AUTOSAR XML (schema 4-3-0)
standard types defined: float32, sint16, uint16, uint32, uint8, float32_DataConstr, sint16_DataConstr, uint16_DataConstr, uint32_DataConstr, uint8_DataConstr, boolean, sint32
package /ASP_DataTypes
  44 x impl type, all with category=VALUE:
    accPedalPosition: base-type=BaseTypes/uint8
    accPedalPositionQual: base-type=BaseTypes/uint8, compu {0=Cx0_Unsafe, 1=Cx1_Safe, 2=Cx2_SNA; unit Enum}
    brakePedalPressed: base-type=boolean, compu {0=Cx0_No, 1=Cx1_Yes; unit Enum}
    brakePedalPressedQual: base-type=BaseTypes/uint8, compu {0=Cx0_Unsafe, 1=Cx1_Safe, 2=Cx2_SNA; unit Enum}
    brakeTorque: base-type=BaseTypes/uint16
    collAvoidSnvtySetting: base-type=BaseTypes/uint8, compu {0=Cx0_NotInUse, 1=Cx1_LoSnvty, 2=Cx2_NormSnvty, 3=Cx3_HiSnvty; unit Enum}
    collAvoidSnvtySettingQual: base-type=BaseTypes/uint8, compu {0=Cx0_Unsafe, 1=Cx1_Safe, 2=Cx2_SNA; unit Enum}
    driverAEBOverride: base-type=boolean, compu {0=Cx0_No, 1=Cx1_Yes; unit Enum}
    driverAEBOverrideQual: base-type=BaseTypes/uint8, compu {0=Cx0_Unsafe, 1=Cx1_Safe, 2=Cx2_SNA; unit Enum}
    driverBrakeTorque: base-type=BaseTypes/uint16
    driverBrakeTorqueQual: base-type=BaseTypes/uint8, compu {0=Cx0_Unsafe, 1=Cx1_Safe, 2=Cx2_SNA; unit Enum}
    dynamicWheelRadiusFront: base-type=BaseTypes/uint16
    dynamicWheelRadiusRear: base-type=BaseTypes/uint16
    engineState: base-type=BaseTypes/uint8, compu {0=Cx0_Stop, 1=Cx1_Start, 2=Cx2_Idle_Unstable (Idle Unstable), 3=Cx3_Idle_Stable (Idle Stable), 4=Cx4_Unlimited, 5=Cx5_Limited, 6=Cx6_SNA; unit Enum}
    frontWheelAngle: base-type=BaseTypes/sint16
    frontWheelAngleQual: base-type=BaseTypes/uint8, compu {0=Cx0_Unavailable, 1=Cx1_Available, 2=Cx2_SNA; unit Enum}
    ignitionState: base-type=BaseTypes/uint8, compu {0=Cx0_Lock, 1=Cx1_OFF, 2=Cx2_ACC, 3=Cx3_ON, 4=Cx4_Start, 5=Cx5_SNA; unit Enum}
    lateralAcceleration: base-type=BaseTypes/sint16
    lateralAccelerationQual: base-type=BaseTypes/uint8, compu {0=Cx0_Unavailable, 1=Cx1_Available, 2=Cx2_SNA; unit Enum}
    lateralAccRaw: base-type=BaseTypes/sint16
    lateralAccRawQual: base-type=BaseTypes/uint8, compu {0=Cx0_Unsafe, 1=Cx1_Safe, 2=Cx2_SNA; unit Enum}
    longitudinalAcceleration: base-type=BaseTypes/sint16
    longitudinalAccelerationQual: base-type=BaseTypes/uint8, compu {0=Cx0_Unavailable, 1=Cx1_Available, 2=Cx2_SNA; unit Enum}
    longitudinalAccRaw: base-type=BaseTypes/sint16
    longitudinalAccRawQual: base-type=BaseTypes/uint8, compu {0=Cx0_Unsafe, 1=Cx1_Safe, 2=Cx2_SNA; unit Enum}
    longitudinalSpeed: base-type=BaseTypes/sint16
    longitudinalSpeedQual: base-type=BaseTypes/uint8, compu {0=Cx0_Unsafe, 1=Cx1_Safe, 2=Cx2_SNA; unit Enum}
    rearWheelAngle: base-type=BaseTypes/sint16
    rearWheelAngleQual: base-type=BaseTypes/uint8, compu {0=Cx0_Unavailable, 1=Cx1_Available, 2=Cx2_SNA; unit Enum}
    steeringWhlAngle: base-type=BaseTypes/sint16
    steeringWhlAngleQual: base-type=BaseTypes/uint8, compu {0=Cx0_Unsafe, 1=Cx1_Safe, 2=Cx2_SNA; unit Enum}
    steeringWhlAngleSpeed: base-type=sint32
    steeringWhlAngleSpeedQual: base-type=BaseTypes/uint8, compu {0=Cx0_Unsafe, 1=Cx1_Safe, 2=Cx2_SNA; unit Enum}
    suspensionType: base-type=BaseTypes/uint8
    turnIndicator: base-type=BaseTypes/uint8
    vehicleMotionState: base-type=BaseTypes/uint8, compu {0=Cx0_Ukwn, 1=Cx1_StandStillVal1, 2=Cx2_StandStillVal2, 3=Cx3_StandStillVal3, 4=Cx4_RollgFwdVal1, 5=Cx5_RollgFwdVal2, 6=Cx6_RollgBackwVal1, 7=Cx7_RollgBackwVal2; unit Enum}
    vehicleMotionStateQual: base-type=BaseTypes/uint8, compu {0=Cx0_Unsafe, 1=Cx1_Safe, 2=Cx2_SNA; unit Enum}
    wheelSpeedFrontLeft: base-type=BaseTypes/sint16
    wheelSpeedFrontRight: base-type=BaseTypes/sint16
    wheelSpeedQual: base-type=BaseTypes/uint8, compu {0=Cx0_Unavailable, 1=Cx1_Available, 2=Cx2_SNA; unit Enum}
    wheelSpeedRearLeft: base-type=BaseTypes/sint16
    wheelSpeedRearRight: base-type=BaseTypes/sint16
    yawRate: base-type=BaseTypes/sint16
    yawRateQual: base-type=BaseTypes/uint8, compu {0=Cx0_Unavailable, 1=Cx1_Available, 2=Cx2_SNA; unit Enum}
package /ASP_DataTypes/Units
  unit U_Enum: display-name=Enum, factor-si-to-unit=1, offset-si-to-unit=0
package /ComponentTypes/HkmcVehicleInputSWC
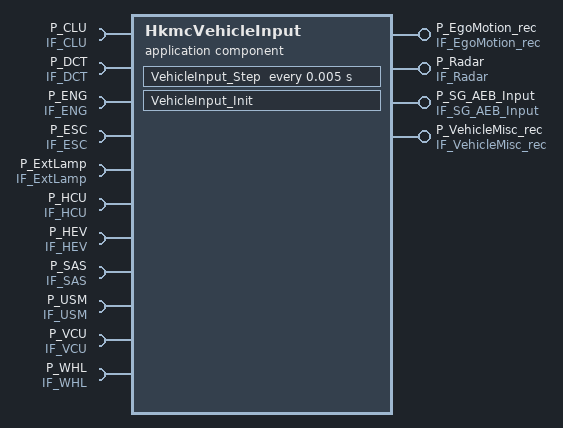
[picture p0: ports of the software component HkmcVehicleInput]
  application sw component type HkmcVehicleInput
    4 x provide port:
      P_EgoMotion_rec: nonqueued-sender-com-spec{data-element=DE_EgoMotion_rec, init-value=constant-reference=CS_VehicleInput_EgoMotion_rec}, provided-interface=IF_EgoMotion_rec
      P_Radar: nonqueued-sender-com-spec{data-element=DE_Radar, init-value=constant-reference=CS_VehicleInput_Radar}, provided-interface=IF_Radar
      P_SG_AEB_Input: nonqueued-sender-com-spec{data-element=DE_SG_AEB_Input, init-value=constant-reference=CS_VehicleInput_SG_AEB_Input}, provided-interface=IF_SG_AEB_Input
      P_VehicleMisc_rec: nonqueued-sender-com-spec{data-element=DE_VehicleMisc_rec, init-value=constant-reference=CS_VehicleInput_VehicleMisc_rec}, provided-interface=IF_VehicleMisc_rec
    11 x require port:
      P_CLU: nonqueued-receiver-com-spec{data-element=DE_CLU, filter=data-filter-type=ALWAYS, init-value=constant-reference=CS_Vehicle_CLU}, required-interface=IF_CLU
      P_DCT: nonqueued-receiver-com-spec{data-element=DE_DCT, filter=data-filter-type=ALWAYS, init-value=constant-reference=CS_VehicleInput_DCT}, required-interface=IF_DCT
      P_ENG: nonqueued-receiver-com-spec{data-element=DE_ENG, filter=data-filter-type=ALWAYS, init-value=constant-reference=CS_VehicleInput_ENG}, required-interface=IF_ENG
      P_ESC: nonqueued-receiver-com-spec{data-element=DE_ESC, filter=data-filter-type=ALWAYS, init-value=constant-reference=CS_VehicleInput_ESC}, required-interface=IF_ESC
      P_ExtLamp: nonqueued-receiver-com-spec{data-element=DE_ExtLamp, filter=data-filter-type=ALWAYS, init-value=constant-reference=CS_VehicleInput_ExtLamp}, required-interface=IF_ExtLamp
      P_HCU: nonqueued-receiver-com-spec{data-element=DE_HCU, filter=data-filter-type=ALWAYS, init-value=constant-reference=CS_Vehicle_HCU}, required-interface=IF_HCU
      P_HEV: nonqueued-receiver-com-spec{data-element=DE_HEV, filter=data-filter-type=ALWAYS, init-value=constant-reference=CS_VehicleInput_HEV}, required-interface=IF_HEV
      P_SAS: nonqueued-receiver-com-spec{data-element=DE_SAS, filter=data-filter-type=ALWAYS, init-value=constant-reference=CS_VehicleInput_SAS}, required-interface=IF_SAS
      P_USM: nonqueued-receiver-com-spec{data-element=DE_USM, filter=data-filter-type=ALWAYS, init-value=constant-reference=CS_VehicleInput_USM}, required-interface=IF_USM
      P_VCU: nonqueued-receiver-com-spec{data-element=DE_VCU, filter=data-filter-type=ALWAYS, init-value=constant-reference=CS_Vehicle_VCU}, required-interface=IF_VCU
      P_WHL: nonqueued-receiver-com-spec{data-element=DE_WHL, filter=data-filter-type=ALWAYS, init-value=constant-reference=CS_VehicleInput_WHL}, required-interface=IF_WHL
    behavior HkmcVehicleInput_InternalBehavior
      init event VehicleInput_InitEvent: start-on-event=VehicleInput_Init
      timing event VehicleInput_Step_TE: start-on-event=VehicleInput_Step, period=0.005
      runnable VehicleInput_Init
        data-receive-point-by-arguments:
          11 x access:
            REC_P_CLU_DE_CLU: accessed-variable=P_CLU.DE_CLU
            REC_P_DCT_DE_DCT: accessed-variable=P_DCT.DE_DCT
            REC_P_ENG_DE_ENG: accessed-variable=P_ENG.DE_ENG
            REC_P_ESC_DE_ESC: accessed-variable=P_ESC.DE_ESC
            REC_P_ExtLamp_DE_ExtLamp: accessed-variable=P_ExtLamp.DE_ExtLamp
            REC_P_HCU_DE_HCU: accessed-variable=P_HCU.DE_HCU
            REC_P_HEV_DE_HEV: accessed-variable=P_HEV.DE_HEV
            REC_P_SAS_DE_SAS: accessed-variable=P_SAS.DE_SAS
            REC_P_USM_DE_USM: accessed-variable=P_USM.DE_USM
            REC_P_VCU_DE_VCU: accessed-variable=P_VCU.DE_VCU
            REC_P_WHL_DE_WHL: accessed-variable=P_WHL.DE_WHL
        data-send-points:
          4 x access:
            SEND_P_EgoMotion_rec_DE_EgoMotion_rec: accessed-variable=P_EgoMotion_rec.DE_EgoMotion_rec
            SEND_P_Radar_DE_Radar: accessed-variable=P_Radar.DE_Radar
            SEND_P_SG_AEB_Input_DE_SG_AEB_Input: accessed-variable=P_SG_AEB_Input.DE_SG_AEB_Input
            SEND_P_VehicleMisc_rec_DE_VehicleMisc_rec: accessed-variable=P_VehicleMisc_rec.DE_VehicleMisc_rec
      runnable VehicleInput_Step
        data-receive-point-by-arguments:
          11 x access:
            REC_P_CLU_DE_CLU: accessed-variable=P_CLU.DE_CLU
            REC_P_DCT_DE_DCT: accessed-variable=P_DCT.DE_DCT
            REC_P_ENG_DE_ENG: accessed-variable=P_ENG.DE_ENG
            REC_P_ESC_DE_ESC: accessed-variable=P_ESC.DE_ESC
            REC_P_ExtLamp_DE_ExtLamp: accessed-variable=P_ExtLamp.DE_ExtLamp
            REC_P_HCU_DE_HCU: accessed-variable=P_HCU.DE_HCU
            REC_P_HEV_DE_HEV: accessed-variable=P_HEV.DE_HEV
            REC_P_SAS_DE_SAS: accessed-variable=P_SAS.DE_SAS
            REC_P_USM_DE_USM: accessed-variable=P_USM.DE_USM
            REC_P_VCU_DE_VCU: accessed-variable=P_VCU.DE_VCU
            REC_P_WHL_DE_WHL: accessed-variable=P_WHL.DE_WHL
        data-send-points:
          4 x access:
            SEND_P_EgoMotion_rec_DE_EgoMotion_rec: accessed-variable=P_EgoMotion_rec.DE_EgoMotion_rec
            SEND_P_Radar_DE_Radar: accessed-variable=P_Radar.DE_Radar
            SEND_P_SG_AEB_Input_DE_SG_AEB_Input: accessed-variable=P_SG_AEB_Input.DE_SG_AEB_Input
            SEND_P_VehicleMisc_rec_DE_VehicleMisc_rec: accessed-variable=P_VehicleMisc_rec.DE_VehicleMisc_rec
  swc implementation HkmcVehicleInput_Implementation: behavior=HkmcVehicleInput_InternalBehavior
    code-descriptors:
      code Default: artifact-descriptors=autosar-engineering-object={short-label=Default, category=SWSRC}
package /ComponentTypes/HkmcVehicleInputSWC/Constants
  15 x constant specification:
    CS_Vehicle_CLU: value-spec=fields=CLU_OdoVal:0
    CS_Vehicle_HCU: value-spec=fields=HCU_HevRdySta:0
    CS_Vehicle_VCU: value-spec=fields=VCU_EVRdySta:0
    CS_VehicleInput_DCT: value-spec=fields=DCT_AccelPdlVal:0
    CS_VehicleInput_EgoMotion_rec: value-spec=fields=[dynamicWheelRadiusRear:0, lateralAccelerationQual:0, lateralAcceleration:0, longitudinalSpeedQual:0, wheelSpeedFrontRight:0, dynamicWheelRadiusFront:0, wheelSpeedQual:0, wheelSpeedFrontLeft:0, longitudinalSpeed:0, rearWheelAngleQual:0, wheelSpeedRearRight:0, longitudinalAccelerationQual:0, frontWheelAngle:0, rearWheelAngle:0, wheelSpeedRearLeft:0, frontWheelAngleQual:0, longitudinalAcceleration:0, yawRate:0, yawRateQual:0, brakeTorque:0]
    CS_VehicleInput_ENG: value-spec=fields=[ENG_IsgOnSta:0, ENG_EngSta:0, ENG_AccelPdlVal:0]
    CS_VehicleInput_ESC: value-spec=fields=[ESC_YawSigSta:0, ESC_LongAccelSigSta:0, ESC_YawRtVal:0, ESC_LongAccelVal:0, ESC_StdStillVal:0, ESC_DrvBrkActvSta:0, ESC_LatAccelVal:0]
    CS_VehicleInput_ExtLamp: value-spec=fields=[ExtLamp_TrnSigLmpLftBlnkngSta:0, ExtLamp_TrnSigLmpRtBlnkngSta:0]
    CS_VehicleInput_HEV: value-spec=fields=HEV_AccelPdlVal:0
    CS_VehicleInput_Radar: value-spec=fields=[SAS_AnglVal:0, ESC_YawRtVal:0, ESC_LatAccelVal:0, ESC_LongAccelVal:0, longitudinalSpeed:0, longitudinalSpeedQual:0, WHL_DirFLVal:0, WHL_DirFRVal:0, WHL_DirRLVal:0, WHL_DirRRVal:0, ENG_EngSta:0, HCU_HevRdySta:0, VCU_EVRdySta:0, ENG_IgnOnSta:0, CLU_OdoVal:0]
    CS_VehicleInput_SAS: value-spec=fields=SAS_AnglVal:0
    CS_VehicleInput_SG_AEB_Input: value-spec=fields=[longitudinalAccRaw:0, steeringWhlAngleSpeedQual:0, lateralAccRawQual:0, brakePedalPressed:0, vehicleMotionState:0, driverBrakeTorqueQual:0, steeringWhlAngle:0, steeringWhlAngleQual:0, accPedalPositionQual:0, collAvoidSnvtySetting:0, longitudinalAccRawQual:0, steeringWhlAngleSpeed:0, driverAEBOverrideQual:0, collAvoidSnvtySettingQual:0, driverAEBOverride:0, accPedalPosition:0, vehicleMotionStateQual:0, driverBrakeTorque:0, brakePedalPressedQual:0, lateralAccRaw:0]
    CS_VehicleInput_USM: value-spec=fields=USM_Fca1stWrngSetReq:0
    CS_VehicleInput_VehicleMisc_rec: value-spec=fields=[suspensionType:0, ignitionState:0, turnIndicator:0, engineState:0]
    CS_VehicleInput_WHL: value-spec=fields=[WHL_SpdFLVal:0, WHL_SpdFRVal:0, WHL_SpdRLVal:0, WHL_SpdRRVal:0, WHL_DirFLVal:0, WHL_DirFRVal:0, WHL_DirRLVal:0, WHL_DirRRVal:0]
package /ComponentTypes/HkmcVehicleInputSWC/DataTypes
  15 x impl type, all with category=STRUCTURE:
    CLU_T: type-emitter=RTE
      element CLU_OdoVal: implementation-data-type=uint32
    DCT_T: type-emitter=RTE
      element DCT_AccelPdlVal: implementation-data-type=uint16
    EgoMotion_rec
      20 x element, all with category=TYPE_REFERENCE:
        dynamicWheelRadiusRear: range raw 0..4095, implementation-data-type=dynamicWheelRadiusRear
        lateralAccelerationQual: range raw 0..3, implementation-data-type=lateralAccelerationQual
        lateralAcceleration: range raw -2048..2047, implementation-data-type=lateralAcceleration
        longitudinalSpeedQual: range raw 0..3, implementation-data-type=longitudinalSpeedQual
        wheelSpeedFrontRight: range raw -8192..8191, implementation-data-type=wheelSpeedFrontRight
        dynamicWheelRadiusFront: range raw 0..4095, implementation-data-type=dynamicWheelRadiusFront
        wheelSpeedQual: range raw 0..3, implementation-data-type=wheelSpeedQual
        wheelSpeedFrontLeft: range raw -8192..8191, implementation-data-type=wheelSpeedFrontLeft
        longitudinalSpeed: range raw -8192..8191, implementation-data-type=longitudinalSpeed
        rearWheelAngleQual: range raw 0..3, implementation-data-type=rearWheelAngleQual
        wheelSpeedRearRight: range raw -8192..8191, implementation-data-type=wheelSpeedRearRight
        longitudinalAccelerationQual: range raw 0..3, implementation-data-type=longitudinalAccelerationQual
        frontWheelAngle: range raw -16384..16383, implementation-data-type=frontWheelAngle
        rearWheelAngle: range raw -16384..16383, implementation-data-type=rearWheelAngle
        wheelSpeedRearLeft: range raw -8192..8191, implementation-data-type=wheelSpeedRearLeft
        frontWheelAngleQual: range raw 0..3, implementation-data-type=frontWheelAngleQual
        longitudinalAcceleration: range raw -2048..2047, implementation-data-type=longitudinalAcceleration
        yawRate: implementation-data-type=yawRate
        yawRateQual: range raw 0..3, implementation-data-type=yawRateQual
        brakeTorque: range raw 0..16383, implementation-data-type=brakeTorque
    ENG_T: type-emitter=RTE
      element ENG_IsgOnSta: implementation-data-type=uint8
      element ENG_EngSta: implementation-data-type=uint8
      element ENG_AccelPdlVal: implementation-data-type=uint16
    ESC_T: type-emitter=RTE
      7 x element, all with category=TYPE_REFERENCE:
        ESC_YawSigSta: implementation-data-type=uint8
        ESC_LongAccelSigSta: implementation-data-type=uint8
        ESC_YawRtVal: implementation-data-type=uint16
        ESC_LongAccelVal: implementation-data-type=uint16
        ESC_StdStillVal: implementation-data-type=uint8
        ESC_DrvBrkActvSta: implementation-data-type=uint8
        ESC_LatAccelVal: implementation-data-type=uint16
    ExtLamp_T: type-emitter=RTE
      element ExtLamp_TrnSigLmpLftBlnkngSta: implementation-data-type=uint8
      element ExtLamp_TrnSigLmpRtBlnkngSta: implementation-data-type=uint8
    HCU_T: type-emitter=RTE
      element HCU_HevRdySta: implementation-data-type=uint8
    HEV_T: type-emitter=RTE
      element HEV_AccelPdlVal: implementation-data-type=uint16
    Radar_T: sw-calibration-access=READ-ONLY, type-emitter=RTE
      15 x element, all with category=TYPE_REFERENCE:
        SAS_AnglVal: implementation-data-type=uint8
        ESC_YawRtVal: implementation-data-type=uint8
        ESC_LatAccelVal: implementation-data-type=uint8
        ESC_LongAccelVal: implementation-data-type=float32
        longitudinalSpeed: implementation-data-type=uint8
        longitudinalSpeedQual: implementation-data-type=uint8
        WHL_DirFLVal: implementation-data-type=uint8
        WHL_DirFRVal: implementation-data-type=uint8
        WHL_DirRLVal: implementation-data-type=uint8
        WHL_DirRRVal: implementation-data-type=uint8
        ENG_EngSta: implementation-data-type=uint8
        HCU_HevRdySta: implementation-data-type=uint8
        VCU_EVRdySta: implementation-data-type=uint8
        ENG_IgnOnSta: implementation-data-type=uint8
        CLU_OdoVal: implementation-data-type=uint32
    SAS_T: type-emitter=RTE
      element SAS_AnglVal: implementation-data-type=sint16
    SG_AEB_Input
      20 x element, all with category=TYPE_REFERENCE:
        longitudinalAccRaw: range raw -16384..16383, implementation-data-type=longitudinalAccRaw
        steeringWhlAngleSpeedQual: range raw 0..3, implementation-data-type=steeringWhlAngleSpeedQual
        lateralAccRawQual: range raw 0..3, implementation-data-type=lateralAccRawQual
        brakePedalPressed: implementation-data-type=brakePedalPressed
        vehicleMotionState: range raw 0..7, implementation-data-type=vehicleMotionState
        driverBrakeTorqueQual: range raw 0..3, implementation-data-type=driverBrakeTorqueQual
        steeringWhlAngle: range raw -16384..16383, implementation-data-type=steeringWhlAngle
        steeringWhlAngleQual: range raw 0..3, implementation-data-type=steeringWhlAngleQual
        accPedalPositionQual: range raw 0..3, implementation-data-type=accPedalPositionQual
        collAvoidSnvtySetting: range raw 0..3, implementation-data-type=collAvoidSnvtySetting
        longitudinalAccRawQual: range raw 0..3, implementation-data-type=longitudinalAccRawQual
        steeringWhlAngleSpeed: range raw -65536..65535, implementation-data-type=steeringWhlAngleSpeed
        driverAEBOverrideQual: range raw 0..3, implementation-data-type=driverAEBOverrideQual
        collAvoidSnvtySettingQual: range raw 0..3, implementation-data-type=collAvoidSnvtySettingQual
        driverAEBOverride: implementation-data-type=driverAEBOverride
        accPedalPosition: range raw 0..100, implementation-data-type=accPedalPosition
        vehicleMotionStateQual: range raw 0..3, implementation-data-type=vehicleMotionStateQual
        driverBrakeTorque: range raw 0..20000, implementation-data-type=driverBrakeTorque
        brakePedalPressedQual: range raw 0..3, implementation-data-type=brakePedalPressedQual
        lateralAccRaw: range raw -16384..16383, implementation-data-type=lateralAccRaw
    USM_T: sw-calibration-access=READ-ONLY, type-emitter=RTE
      element USM_Fca1stWrngSetReq: implementation-data-type=uint8
    VCU_T: type-emitter=RTE
      element VCU_EVRdySta: implementation-data-type=uint8
    VehicleMisc_rec
      4 x element, all with category=TYPE_REFERENCE, range raw 0..7:
        suspensionType: implementation-data-type=suspensionType
        ignitionState: implementation-data-type=ignitionState
        turnIndicator: implementation-data-type=turnIndicator
        engineState: implementation-data-type=engineState
    WHL_T: type-emitter=RTE
      8 x element, all with category=TYPE_REFERENCE:
        WHL_SpdFLVal: implementation-data-type=uint16
        WHL_SpdFRVal: implementation-data-type=uint16
        WHL_SpdRLVal: implementation-data-type=uint16
        WHL_SpdRRVal: implementation-data-type=uint16
        WHL_DirFLVal: implementation-data-type=uint8
        WHL_DirFRVal: implementation-data-type=uint8
        WHL_DirRLVal: implementation-data-type=uint8
        WHL_DirRRVal: implementation-data-type=uint8
package /ComponentTypes/HkmcVehicleInputSWC/PortInterfaces
  15 x sender receiver interface:
    IF_CLU: invalidation-policy{data-element=DE_CLU, handle-invalid=DONT-INVALIDATE}
      data DE_CLU: type=CLU_T
    IF_DCT: invalidation-policy{data-element=DE_DCT, handle-invalid=DONT-INVALIDATE}
      data DE_DCT: type=DCT_T
    IF_EgoMotion_rec: invalidation-policy{data-element=DE_EgoMotion_rec, handle-invalid=DONT-INVALIDATE}
      data DE_EgoMotion_rec: type=EgoMotion_rec
    IF_ENG: invalidation-policy{data-element=DE_ENG, handle-invalid=DONT-INVALIDATE}
      data DE_ENG: type=ENG_T
    IF_ESC: invalidation-policy{data-element=DE_ESC, handle-invalid=DONT-INVALIDATE}
      data DE_ESC: type=ESC_T
    IF_ExtLamp: invalidation-policy{data-element=DE_ExtLamp, handle-invalid=DONT-INVALIDATE}
      data DE_ExtLamp: type=ExtLamp_T
    IF_HCU: invalidation-policy{data-element=DE_HCU, handle-invalid=DONT-INVALIDATE}
      data DE_HCU: type=HCU_T
    IF_HEV: invalidation-policy{data-element=DE_HEV, handle-invalid=DONT-INVALIDATE}
      data DE_HEV: type=HEV_T
    IF_Radar: invalidation-policy{data-element=DE_Radar, handle-invalid=DONT-INVALIDATE}
      data DE_Radar: type=Radar_T
    IF_SAS: invalidation-policy{data-element=DE_SAS, handle-invalid=DONT-INVALIDATE}
      data DE_SAS: type=SAS_T
    IF_SG_AEB_Input: invalidation-policy{data-element=DE_SG_AEB_Input, handle-invalid=DONT-INVALIDATE}
      data DE_SG_AEB_Input: type=SG_AEB_Input
    IF_USM: invalidation-policy{data-element=DE_USM, handle-invalid=DONT-INVALIDATE}
      data DE_USM: type=USM_T
    IF_VCU: invalidation-policy{data-element=DE_VCU, handle-invalid=DONT-INVALIDATE}
      data DE_VCU: type=VCU_T
    IF_VehicleMisc_rec: invalidation-policy{data-element=DE_VehicleMisc_rec, handle-invalid=DONT-INVALIDATE}
      data DE_VehicleMisc_rec: type=VehicleMisc_rec
    IF_WHL: invalidation-policy{data-element=DE_WHL, handle-invalid=DONT-INVALIDATE}
      data DE_WHL: type=WHL_T
